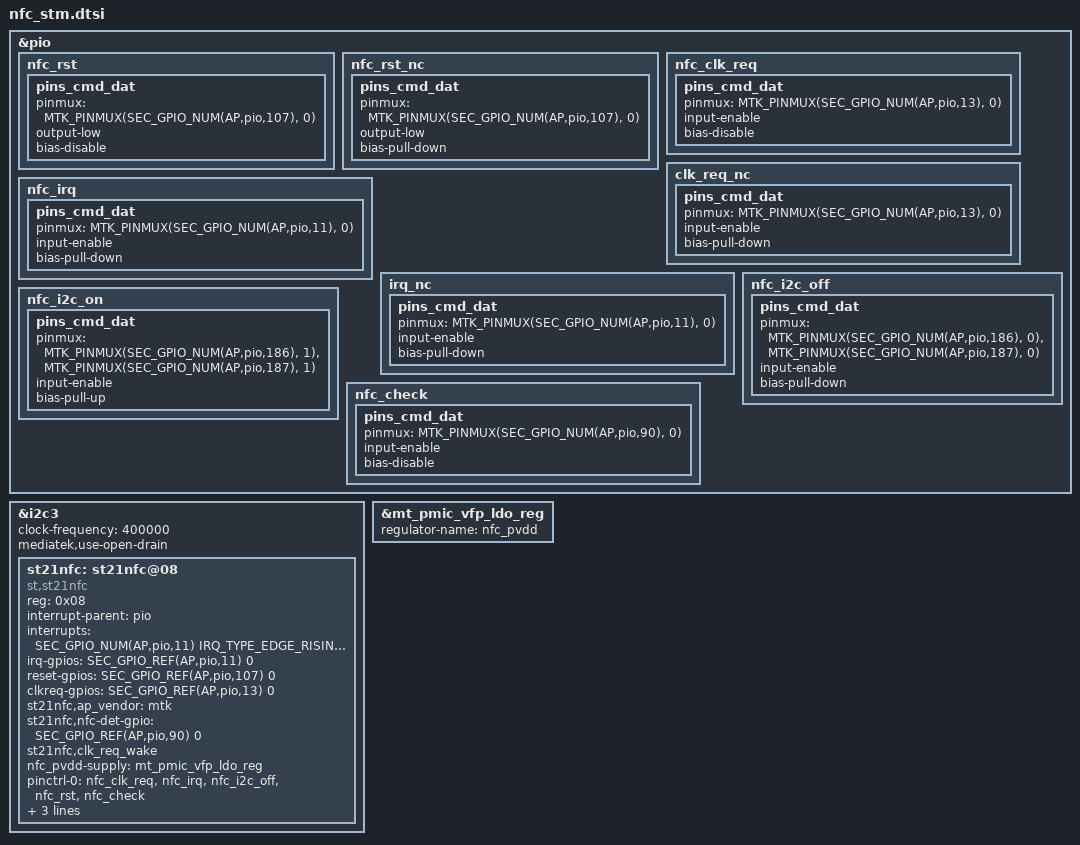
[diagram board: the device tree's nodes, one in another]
/*
 * This program is free software; you can redistribute it and/or modify
 * it under the terms of the GNU General Public License version 2 and
 * only version 2 as published by the Free Software Foundation.
 *
 * This program is distributed in the hope that it will be useful,
 * but WITHOUT ANY WARRANTY; without even the implied warranty of
 * MERCHANTABILITY or FITNESS FOR A PARTICULAR PURPOSE.  See the
 * GNU General Public License for more details.
 */
#include <dt-bindings/pinctrl/mt6877-pinfunc.h>
&pio {
	nfc_rst: nfc_rst {
		pins_cmd_dat {
			pinmux = <MTK_PINMUX(SEC_GPIO_NUM(AP,pio,107), 0)>;
			output-low;
			bias-disable;
		};
	};
	nfc_rst_nc: nfc_rst_nc {
		pins_cmd_dat {
			pinmux = <MTK_PINMUX(SEC_GPIO_NUM(AP,pio,107), 0)>;
			output-low;
			bias-pull-down;
		};
	};
};
&pio {
	nfc_clk_req: nfc_clk_req {
		pins_cmd_dat{
			pinmux =  <MTK_PINMUX(SEC_GPIO_NUM(AP,pio,13), 0)>;
			input-enable;
			bias-disable;
		};
	};
	clk_req_nc: clk_req_nc {
		pins_cmd_dat{
			pinmux =  <MTK_PINMUX(SEC_GPIO_NUM(AP,pio,13), 0)>;
			input-enable;
			bias-pull-down;
		};
	};
};

&pio {
	nfc_irq: nfc_irq {
		pins_cmd_dat {
			pinmux = <MTK_PINMUX(SEC_GPIO_NUM(AP,pio,11), 0)>;
			input-enable;
			bias-pull-down;
		};
	};

	irq_nc: irq_nc {
		pins_cmd_dat {
			pinmux = <MTK_PINMUX(SEC_GPIO_NUM(AP,pio,11), 0)>;
			input-enable;
			bias-pull-down;
		};
	};
};

&pio {
	nfc_i2c_off: nfc_i2c_off {
		pins_cmd_dat {
			pinmux = <MTK_PINMUX(SEC_GPIO_NUM(AP,pio,186), 0)>,
				<MTK_PINMUX(SEC_GPIO_NUM(AP,pio,187), 0)>;
			input-enable;
			bias-pull-down;
		};
	};
	nfc_i2c_on: nfc_i2c_on {
		pins_cmd_dat {
			pinmux = <MTK_PINMUX(SEC_GPIO_NUM(AP,pio,186), 1)>,
				<MTK_PINMUX(SEC_GPIO_NUM(AP,pio,187), 1)>;
			input-enable;
			bias-pull-up;
		};
	};
};

#if 1
&pio {
	nfc_check: nfc_check {
		pins_cmd_dat {
			pinmux = <MTK_PINMUX(SEC_GPIO_NUM(AP,pio,90), 0)>;
			input-enable;
			bias-disable;
		};
	};
};
#endif

&i2c3 {
	status = "ok";
	#address-cells = <1>;
	#size-cells = <0>;
	clock-frequency = <400000>;
	mediatek,use-open-drain;

	st21nfc: st21nfc@08 {
		compatible = "st,st21nfc";
		reg = <0x08>;
		interrupt-parent = <&pio>;
		interrupts = <SEC_GPIO_NUM(AP,pio,11) IRQ_TYPE_EDGE_RISING
			SEC_GPIO_NUM(AP,pio,11) 0>;
		irq-gpios = <SEC_GPIO_REF(AP,pio,11) 0>;
		reset-gpios = <SEC_GPIO_REF(AP,pio,107) 0>;
		/*pidle-gpios = <&tlmm 48 0x00>;*/
		clkreq-gpios = <SEC_GPIO_REF(AP,pio,13) 0>;
		st21nfc,ap_vendor = "mtk";
#if 1
		st21nfc,nfc-det-gpio = <SEC_GPIO_REF(AP,pio,90) 0>;
#endif
#if 0
		st21nfc,late_pvdd_en;
#endif
#if 1
		st21nfc,clk_req_wake;
#endif
#if 1
		nfc_pvdd-supply = <&mt_pmic_vfp_ldo_reg>;
#endif
		pinctrl-names = "default", "nfc_nc", "nfc_on", "i2c_off";
		pinctrl-0 = <&nfc_clk_req &nfc_irq &nfc_i2c_off &nfc_rst
#if 1
			&nfc_check
#endif
			>;
		pinctrl-1 = <&clk_req_nc &irq_nc &nfc_rst_nc>;
		pinctrl-2 = <&nfc_i2c_on>;
		pinctrl-3 = <&nfc_i2c_off>;

	};
};

&mt_pmic_vfp_ldo_reg {
	regulator-name = "nfc_pvdd";
};

